# CM41x_M0 register map
Vendor: Analog Devices; Series: CM41x_M0; File version: 1p0
CPU: CM0 r0p0, little endian, MPU, FPU, 4 interrupt priority bits
Registers are 32-bit, read-write, reset 0x0 unless marked. A register's access mark holds for its fields unless they carry their own. Offsets are from the block's base; [hi:lo] are bit positions; lines under a group give offsets from that group; {n}, {i} and the like mark numbered series.

## MBOX0_PORT0 — MBOX Port 0 register map
Base 0x400D0000
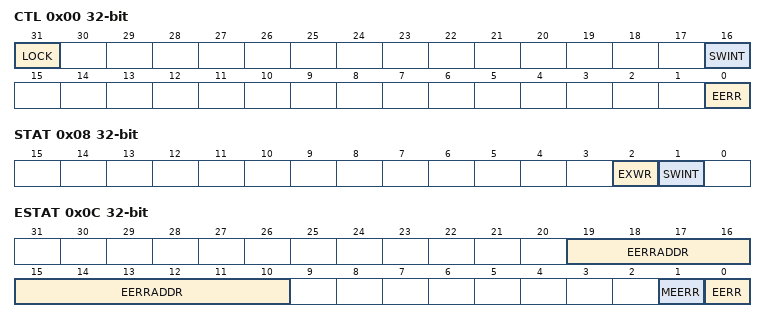
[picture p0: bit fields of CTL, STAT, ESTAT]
0x00 CTL — Port 0 Control Register
  [31] LOCK range 0x00000000..0x00000001 — Lock Enable
  [16] SWINT range 0x00000000..0x00000001 — Enable Software Interrupt
  [0] EERR range 0x00000000..0x00000001 — Enable Error Interrupt
0x04 FORCEIRQ — Port 0 Force IRQ Register
  [0] SWIRQ range 0x00000000..0x00000001 — Initiate Software Interrupt Request to Port 1
0x08 STAT — Port 0 Status Register
  [2] EXWR ro — Port 0 Exclusive Write Status
  [1] SWINT range 0x00000000..0x00000001 — Software Interrupt Status
0x0C ESTAT — Port 0 ECC Status Register
  [19:10] EERRADDR ro — EEC Error Address
  [1] MEERR range 0x00000000..0x00000001 — Multiple ECC Multi-bit Errors Detected
  [0] EERR range 0x00000000..0x00000001 — ECC Multi-bit Error

## MBOX0_PORT1 — MBOX Port 1 register map
Base 0x400D1000
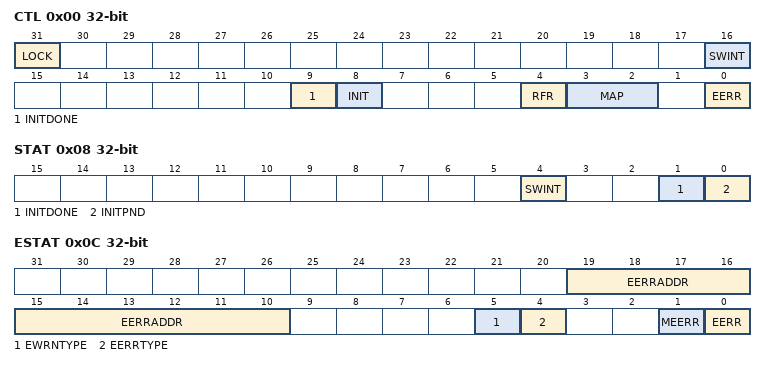
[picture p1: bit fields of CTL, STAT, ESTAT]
0x00 CTL — Port 1 Control Register
  [31] LOCK range 0x00000000..0x00000001 — Lock Enable
  [16] SWINT range 0x00000000..0x00000001 — Enable Software Interrupt to Port 1
  [9] INITDONE range 0x00000000..0x00000001 — Enable Interrupt on Memory Initialization Completion
  [8] INIT range 0x00000000..0x00000001 — Enable Memory Initialization
  [4] RFR range 0x00000000..0x00000001 — Enable Auto-Refresh of ECC States
  [3:2] MAP — Select ECC Map Mode
    0=NORMAL (Enable ECC normal mode.); 2=MAP_DATA (Enable ECC Map Data Mode.); 3=MAP_ECC (Enable ECC map parity mode.)
  [0] EERR range 0x00000000..0x00000001 — Enable Interrupt on ECC Error
0x04 FORCEIRQ — Port 1 Force IRQ Register
  [0] SWIRQ range 0x00000000..0x00000001 — Initiate Software Interrupt Request to Port 0
0x08 STAT — Port 1 Status Register
  [4] SWINT range 0x00000000..0x00000001 — Software Interrupt Status to Port 1
  [1] INITDONE range 0x00000000..0x00000001 — Initialization Done Interrupt Status
  [0] INITPND ro — Initialization Pending Status
0x0C ESTAT — Port 1 ECC Status Register
  [19:10] EERRADDR ro — Bits [11:2] of the Address
  [5] EWRNTYPE ro — ECC Single Bit Error Access Type
  [4] EERRTYPE ro — ECC Multi-bit Error Access Type
  [1] MEERR range 0x00000000..0x00000001 — Multiple ECC Multi-bit Errors Detected
  [0] EERR range 0x00000000..0x00000001 — ECC Multi-bit Error
0x10 RFRPER — Auto-refresh Period Register
  [31:0] VALUE range 0x00000000..0xFFFFFFFF — ECC Memory Auto-refresh Period
0x14 RFRADDR — Auto-refresh Address Register
  [11:2] VALUE range 0x00000000..0x000003FF — Auto-refresh Address Value
0x18 RFRCNT reset 0x1 — Auto-refresh Counter Register
  [31:0] VALUE range 0x00000000..0xFFFFFFFF — ECC Auto-refresh Count Down Counter Value

## SWU0 — System Watchpoint Unit
Base 0x410F0000
Same registers: SWU2 0x400F0000, SWU3 0x400F1000, SWU4 0x400F2000, SWU5 0x400F3000, SWU6 0x400F4000, SWU1 0x410F1000
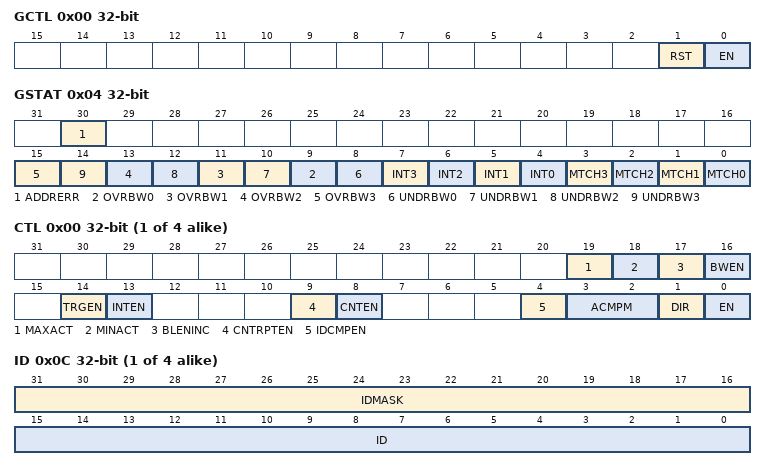
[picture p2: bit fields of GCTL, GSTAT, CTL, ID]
0x00 GCTL — Global Control Register
  [1] RST — Global Reset
  [0] EN — Global Enable
0x04 GSTAT — Global Status Register
  [30] ADDRERR — Address Error Status
  [2n+9] OVRBW{n} (n=0..3) — Group {n} Bandwidth Above Maximum Target
  [2n+8] UNDRBW{n} (n=0..3) — Group {n} Bandwidth Below Minimum Target
  [n+4] INT{n} (n=0..3) — Group {n} Interrupt Status
  [n] MTCH{n} (n=0..3) — Group {n} Match
{0x10+0x20*i} WB[{i}] (i=0..3) group — WB block
  0x00 CTL — Control Register n
    [19] MAXACT — Action for Bandwidth Above Maximum
    [18] MINACT — Action for Bandwidth Below Minimum
    [17] BLENINC — Increment Bandwidth Count by Burst Length
    [16] BWEN — Bandwidth Mode Enable
    [14] TRGEN — Trigger Enable
    [13] INTEN — Interrupt Enable
    [9] CNTRPTEN — Count Repeat Enable
    [8] CNTEN — Count Enable
    [4] IDCMPEN range 0x00000000..0x00000001 — ID Comparison Enable
    [3:2] ACMPM — Address Comparison Mode
    [1] DIR — Transaction Direction for Match
    [0] EN — Enable Watchpoint
  0x04 LA — Lower Address Register n
    [31:0] ADDR range 0x00000000..0xFFFFFFFF — Lower Address
  0x08 UA — Upper Address Register n
    [31:0] ADDR range 0x00000000..0xFFFFFFFF — Upper Address
  0x0C ID — ID Register n
    [31:16] IDMASK range 0x00000000..0x0000FFFF — Identity Mask (for Or with ID)
    [15:0] ID range 0x00000000..0x0000FFFF — Identity
  0x10 CNT — Count Register n
    [15:0] COUNT range 0x00000000..0x0000FFFF
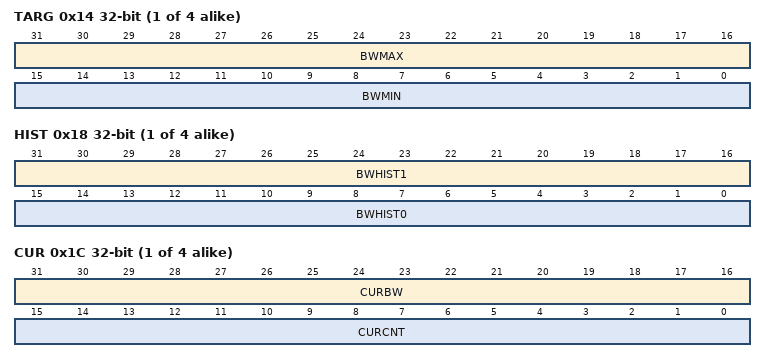
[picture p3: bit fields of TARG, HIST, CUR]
  0x14 TARG — Target Register n
    [31:16] BWMAX range 0x00000000..0x0000FFFF — Maximum Bandwidth Target
    [15:0] BWMIN range 0x00000000..0x0000FFFF — Minimum Bandwidth Target
  0x18 HIST — Bandwidth History Register n
    [31:16] BWHIST1 ro — Bandwidth from Window Before Last
    [15:0] BWHIST0 ro — Bandwidth from Last Window
  0x1C CUR — Current Register n
    [31:16] CURBW ro — Current Bandwidth
    [15:0] CURCNT ro — Current Count
